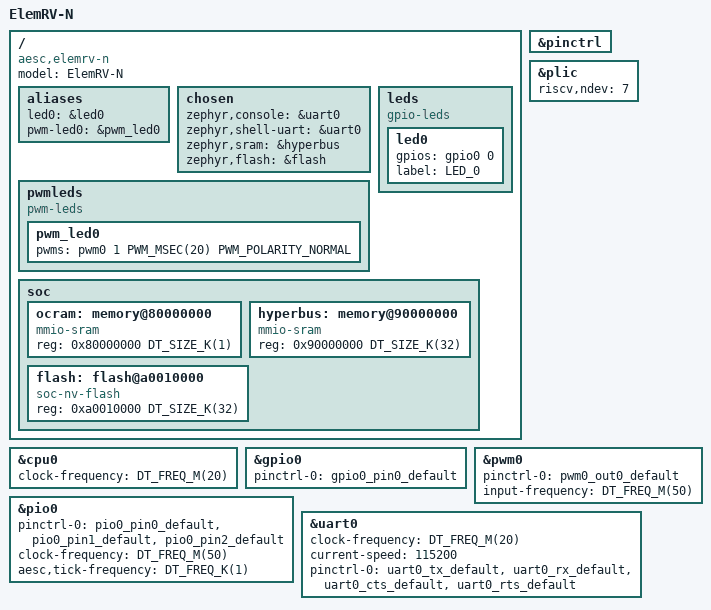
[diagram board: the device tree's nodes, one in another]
/*
 * SPDX-FileCopyrightText: 2025 Aesc Silicon
 *
 * SPDX-License-Identifier: Apache-2.0
 */

/dts-v1/;

#include <aesc/elemrv-n.dtsi>
#include <zephyr/dt-bindings/pwm/pwm.h>
#include "elemrv_elemrv_n-pinctrl.dtsi"

/ {
	model = "ElemRV-N";
	compatible = "aesc,elemrv-n";

	aliases {
		led0 = &led0;
		pwm-led0 = &pwm_led0;
	};

	chosen {
		zephyr,console = &uart0;
		zephyr,shell-uart = &uart0;
		zephyr,sram = &hyperbus;
		zephyr,flash = &flash;
	};

	leds: leds {
		compatible = "gpio-leds";

		led0: led0 {
			gpios = <&gpio0 0 GPIO_ACTIVE_HIGH>;
			label = "LED_0";
		};
	};

	pwmleds {
		compatible = "pwm-leds";

		pwm_led0: pwm_led0 {
			pwms = <&pwm0 1 PWM_MSEC(20) PWM_POLARITY_NORMAL>;
		};
	};

	soc {
		ocram: memory@80000000 {
			device_type = "memory";
			compatible = "mmio-sram";
			reg = <0x80000000 DT_SIZE_K(1)>;
		};

		hyperbus: memory@90000000 {
			device_type = "memory";
			compatible = "mmio-sram";
			reg = <0x90000000 DT_SIZE_K(32)>;
		};

		flash: flash@a0010000 {
			compatible = "soc-nv-flash";
			reg = <0xa0010000 DT_SIZE_K(32)>;
		};
	};
};

&cpu0 {
	clock-frequency = <DT_FREQ_M(20)>;
};

&gpio0 {
	status = "okay";
	pinctrl-0 = <&gpio0_pin0_default>;
	pinctrl-names = "default";
};

&pinctrl {
	status = "okay";
};

&pio0 {
	pinctrl-0 = <&pio0_pin0_default &pio0_pin1_default &pio0_pin2_default>;
	pinctrl-names = "default";
	clock-frequency = <DT_FREQ_M(50)>;
	aesc,tick-frequency = <DT_FREQ_K(1)>;
	status = "okay";
};

&plic {
	riscv,ndev = <7>;
};

&pwm0 {
	pinctrl-0 = <&pwm0_out0_default>;
	pinctrl-names = "default";
	input-frequency = <DT_FREQ_M(50)>;
	status = "okay";
};

&uart0 {
	clock-frequency = <DT_FREQ_M(20)>;
	current-speed = <115200>;
	pinctrl-0 = <&uart0_tx_default
		     &uart0_rx_default
		     &uart0_cts_default
		     &uart0_rts_default>;
	pinctrl-names = "default";
	status = "okay";
};
